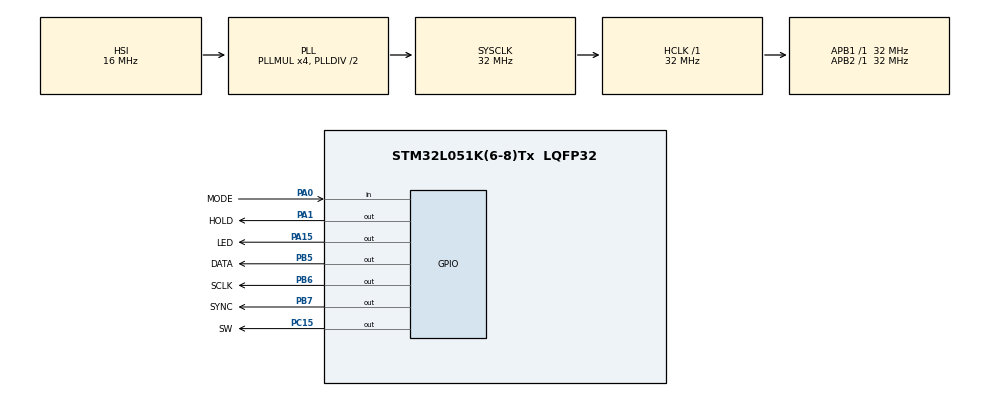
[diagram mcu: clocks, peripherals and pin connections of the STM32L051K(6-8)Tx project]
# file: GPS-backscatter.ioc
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Mcu.Family=STM32L0
Mcu.Name=STM32L051K(6-8)Tx
Mcu.Package=LQFP32
NVIC.TIM2_IRQn=true\:0\:0\:false\:false\:true\:true\:true
PA0.GPIO_Label=MODE
PA0.GPIO_PuPd=GPIO_PULLDOWN
PA0.Signal=GPIO_Input
PA1.GPIO_Label=HOLD
PA1.GPIO_PuPd=GPIO_PULLUP
PA1.PinState=GPIO_PIN_SET
PA1.Signal=GPIO_Output
PA13.Mode=Serial_Wire
PA13.Signal=SYS_SWDIO
PA14.Mode=Serial_Wire
PA14.Signal=SYS_SWCLK
PA15.GPIO_Label=LED
PA15.Signal=GPIO_Output
PB5.GPIO_Label=DATA
PB5.GPIO_PuPd=GPIO_PULLDOWN
PB5.GPIO_Speed=GPIO_SPEED_FREQ_VERY_HIGH
PB5.Signal=GPIO_Output
PB6.GPIO_Label=SCLK
PB6.GPIO_PuPd=GPIO_PULLDOWN
PB6.GPIO_Speed=GPIO_SPEED_FREQ_VERY_HIGH
PB6.Signal=GPIO_Output
PB7.GPIO_Label=SYNC
PB7.GPIO_PuPd=GPIO_PULLUP
PB7.GPIO_Speed=GPIO_SPEED_FREQ_VERY_HIGH
PB7.PinState=GPIO_PIN_SET
PB7.Signal=GPIO_Output
PC15-OSC32_OUT.GPIO_Label=SW
PC15-OSC32_OUT.GPIO_PuPd=GPIO_PULLDOWN
PC15-OSC32_OUT.PinState=GPIO_PIN_RESET
PC15-OSC32_OUT.Signal=GPIO_Output
ProjectManager.HeapSize=0x200
ProjectManager.StackSize=0x400
ProjectManager.TargetToolchain=MDK-ARM V5
RCC.AHBFreq_Value=32000000
RCC.APB1Freq_Value=32000000
RCC.APB1TimFreq_Value=32000000
RCC.APB2Freq_Value=32000000
RCC.APB2TimFreq_Value=32000000
RCC.HCLKFreq_Value=32000000
RCC.HSI16_VALUE=16000000
RCC.HSI_VALUE=16000000
RCC.MSI_VALUE=2097000
RCC.PLLMUL=RCC_PLLMUL_4
RCC.SYSCLKFreq_VALUE=32000000
RCC.SYSCLKSource=RCC_SYSCLKSOURCE_PLLCLK
RCC.VCOOutputFreq_Value=64000000
TIM2.AutoReloadPreload=TIM_AUTORELOAD_PRELOAD_ENABLE
TIM2.Channel-PWM\ Generation1\ No\ Output=TIM_CHANNEL_1
TIM2.ClockDivision=TIM_CLOCKDIVISION_DIV1
TIM2.Period=3999
TIM2.Prescaler=3999
VP_TIM2_VS_ClockSourceINT.Mode=Internal
VP_TIM2_VS_no_output1.Mode=PWM Generation1 No Output
board=custom

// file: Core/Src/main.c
/* USER CODE BEGIN Header */
/**
  ******************************************************************************
  * @file           : main.c
  * @brief          : Main program body
  ******************************************************************************
  * @attention
  *
  * <h2><center>&copy; Copyright (c) 2021 STMicroelectronics.
  * All rights reserved.</center></h2>
  *
  * This software component is licensed by ST under BSD 3-Clause license,
  * the "License"; You may not use this file except in compliance with the
  * License. You may obtain a copy of the License at:
  *                        opensource.org/licenses/BSD-3-Clause
  *
  ******************************************************************************
  */
/* USER CODE END Header */
#include "main.h"

/* USER CODE BEGIN Includes */
#include "user_dac.h"
/* USER CODE END Includes */

TIM_HandleTypeDef htim2;

void SystemClock_Config(void);
static void MX_GPIO_Init(void);
static void MX_TIM2_Init(void);

int main(void)
{

  /* MCU Configuration--------------------------------------------------------*/

  /* Reset of all peripherals, Initializes the Flash interface and the Systick. */
  HAL_Init();

  /* Configure the system clock */
  SystemClock_Config();

  /* Initialize all configured peripherals */
  MX_GPIO_Init();
  MX_TIM2_Init();
  /* USER CODE BEGIN 2 */

//  user_dacInit();
  user_dacTest();

  HAL_TIM_Base_Start_IT(&htim2);

  /* USER CODE END 2 */

  /* Infinite loop */
  /* USER CODE BEGIN WHILE */
  while (1)
  {
    HAL_Delay(1000);
    /* USER CODE END WHILE */

  }
}

void SystemClock_Config(void)
{
  RCC_OscInitTypeDef RCC_OscInitStruct = {0};
  RCC_ClkInitTypeDef RCC_ClkInitStruct = {0};

  /** Configure the main internal regulator output voltage
  */
  __HAL_PWR_VOLTAGESCALING_CONFIG(PWR_REGULATOR_VOLTAGE_SCALE1);
  /** Initializes the RCC Oscillators according to the specified parameters
  * in the RCC_OscInitTypeDef structure.
  */
  RCC_OscInitStruct.OscillatorType = RCC_OSCILLATORTYPE_HSI;
  RCC_OscInitStruct.HSIState = RCC_HSI_ON;
  RCC_OscInitStruct.HSICalibrationValue = RCC_HSICALIBRATION_DEFAULT;
  RCC_OscInitStruct.PLL.PLLState = RCC_PLL_ON;
  RCC_OscInitStruct.PLL.PLLSource = RCC_PLLSOURCE_HSI;
  RCC_OscInitStruct.PLL.PLLMUL = RCC_PLLMUL_4;
  RCC_OscInitStruct.PLL.PLLDIV = RCC_PLLDIV_2;
  if (HAL_RCC_OscConfig(&RCC_OscInitStruct) != HAL_OK)
  {
    Error_Handler();
  }
  /** Initializes the CPU, AHB and APB buses clocks
  */
  RCC_ClkInitStruct.ClockType = RCC_CLOCKTYPE_HCLK|RCC_CLOCKTYPE_SYSCLK
                              |RCC_CLOCKTYPE_PCLK1|RCC_CLOCKTYPE_PCLK2;
  RCC_ClkInitStruct.SYSCLKSource = RCC_SYSCLKSOURCE_PLLCLK;
  RCC_ClkInitStruct.AHBCLKDivider = RCC_SYSCLK_DIV1;
  RCC_ClkInitStruct.APB1CLKDivider = RCC_HCLK_DIV1;
  RCC_ClkInitStruct.APB2CLKDivider = RCC_HCLK_DIV1;

  if (HAL_RCC_ClockConfig(&RCC_ClkInitStruct, FLASH_LATENCY_1) != HAL_OK)
  {
    Error_Handler();
  }
}

static void MX_TIM2_Init(void)
{

  TIM_ClockConfigTypeDef sClockSourceConfig = {0};
  TIM_MasterConfigTypeDef sMasterConfig = {0};
  TIM_OC_InitTypeDef sConfigOC = {0};

  htim2.Instance = TIM2;
  htim2.Init.Prescaler = 3999;
  htim2.Init.CounterMode = TIM_COUNTERMODE_UP;
  htim2.Init.Period = 3999;
  htim2.Init.ClockDivision = TIM_CLOCKDIVISION_DIV1;
  htim2.Init.AutoReloadPreload = TIM_AUTORELOAD_PRELOAD_ENABLE;
  if (HAL_TIM_Base_Init(&htim2) != HAL_OK)
  {
    Error_Handler();
  }
  sClockSourceConfig.ClockSource = TIM_CLOCKSOURCE_INTERNAL;
  if (HAL_TIM_ConfigClockSource(&htim2, &sClockSourceConfig) != HAL_OK)
  {
    Error_Handler();
  }
  if (HAL_TIM_PWM_Init(&htim2) != HAL_OK)
  {
    Error_Handler();
  }
  sMasterConfig.MasterOutputTrigger = TIM_TRGO_RESET;
  sMasterConfig.MasterSlaveMode = TIM_MASTERSLAVEMODE_DISABLE;
  if (HAL_TIMEx_MasterConfigSynchronization(&htim2, &sMasterConfig) != HAL_OK)
  {
    Error_Handler();
  }
  sConfigOC.OCMode = TIM_OCMODE_PWM1;
  sConfigOC.Pulse = 0;
  sConfigOC.OCPolarity = TIM_OCPOLARITY_HIGH;
  sConfigOC.OCFastMode = TIM_OCFAST_DISABLE;
  if (HAL_TIM_PWM_ConfigChannel(&htim2, &sConfigOC, TIM_CHANNEL_1) != HAL_OK)
  {
    Error_Handler();
  }

}

static void MX_GPIO_Init(void)
{
  GPIO_InitTypeDef GPIO_InitStruct = {0};

  /* GPIO Ports Clock Enable */
  __HAL_RCC_GPIOC_CLK_ENABLE();
  __HAL_RCC_GPIOA_CLK_ENABLE();
  __HAL_RCC_GPIOB_CLK_ENABLE();

  /*Configure GPIO pin Output Level */
  HAL_GPIO_WritePin(SW_GPIO_Port, SW_Pin, GPIO_PIN_RESET);

  /*Configure GPIO pin Output Level */
  HAL_GPIO_WritePin(HOLD_GPIO_Port, HOLD_Pin, GPIO_PIN_SET);

  /*Configure GPIO pin Output Level */
  HAL_GPIO_WritePin(LED_GPIO_Port, LED_Pin, GPIO_PIN_RESET);

  /*Configure GPIO pin Output Level */
  HAL_GPIO_WritePin(GPIOB, DATA_Pin|SCLK_Pin, GPIO_PIN_RESET);

  /*Configure GPIO pin Output Level */
  HAL_GPIO_WritePin(SYNC_GPIO_Port, SYNC_Pin, GPIO_PIN_SET);

  /*Configure GPIO pin : SW_Pin */
  GPIO_InitStruct.Pin = SW_Pin;
  GPIO_InitStruct.Mode = GPIO_MODE_OUTPUT_PP;
  GPIO_InitStruct.Pull = GPIO_PULLDOWN;
  GPIO_InitStruct.Speed = GPIO_SPEED_FREQ_LOW;
  HAL_GPIO_Init(SW_GPIO_Port, &GPIO_InitStruct);

  /*Configure GPIO pin : MODE_Pin */
  GPIO_InitStruct.Pin = MODE_Pin;
  GPIO_InitStruct.Mode = GPIO_MODE_INPUT;
  GPIO_InitStruct.Pull = GPIO_PULLDOWN;
  HAL_GPIO_Init(MODE_GPIO_Port, &GPIO_InitStruct);

  /*Configure GPIO pin : HOLD_Pin */
  GPIO_InitStruct.Pin = HOLD_Pin;
  GPIO_InitStruct.Mode = GPIO_MODE_OUTPUT_PP;
  GPIO_InitStruct.Pull = GPIO_PULLUP;
  GPIO_InitStruct.Speed = GPIO_SPEED_FREQ_LOW;
  HAL_GPIO_Init(HOLD_GPIO_Port, &GPIO_InitStruct);

  /*Configure GPIO pin : LED_Pin */
  GPIO_InitStruct.Pin = LED_Pin;
  GPIO_InitStruct.Mode = GPIO_MODE_OUTPUT_PP;
  GPIO_InitStruct.Pull = GPIO_NOPULL;
  GPIO_InitStruct.Speed = GPIO_SPEED_FREQ_LOW;
  HAL_GPIO_Init(LED_GPIO_Port, &GPIO_InitStruct);

  /*Configure GPIO pins : DATA_Pin SCLK_Pin */
  GPIO_InitStruct.Pin = DATA_Pin|SCLK_Pin;
  GPIO_InitStruct.Mode = GPIO_MODE_OUTPUT_PP;
  GPIO_InitStruct.Pull = GPIO_PULLDOWN;
  GPIO_InitStruct.Speed = GPIO_SPEED_FREQ_VERY_HIGH;
  HAL_GPIO_Init(GPIOB, &GPIO_InitStruct);

  /*Configure GPIO pin : SYNC_Pin */
  GPIO_InitStruct.Pin = SYNC_Pin;
  GPIO_InitStruct.Mode = GPIO_MODE_OUTPUT_PP;
  GPIO_InitStruct.Pull = GPIO_PULLUP;
  GPIO_InitStruct.Speed = GPIO_SPEED_FREQ_VERY_HIGH;
  HAL_GPIO_Init(SYNC_GPIO_Port, &GPIO_InitStruct);

}

void Error_Handler(void)
{
}

/************************ (C) COPYRIGHT STMicroelectronics *****END OF FILE****/
